# USBTLLHS_ULPI register map
Vendor: Texas Instruments
Peripheral module from a debugger description file (folder omap4460).
Registers are 8-bit, access per field, reset values left out (the file's numbers can be read two ways) unless marked. A register's access mark holds for its fields unless they carry their own. Offsets are as the file gives them; lines under a group give offsets from that group; [hi:lo] are bit positions; {n}, {i} and the like mark numbered series; 'fields as' and 'values as' point back to an identical list; <NAME> marks a mode.

## USBTLLHS_ULPI
0x00 VENDOR_ID_LO_i_0 ro — Lower byte of USB-IF-supplied 16-bit vendor ID Value is set for all channels. Default is Texas Instruments Vendor ID = 0x0451.
  [7:0] VENDOR_ID_LO
0x01 VENDOR_ID_HI_i_0 ro — Upper byte of USB-IF-supplied 16-bit vendor ID Value is set for all channels. Default is Texas-Instruments Vendor ID = 0x0451.
  [7:0] VENDOR_ID_HI
0x02 PRODUCT_ID_LO_i_0 ro — Lower byte of 16-bit product ID Value is set for all channels. Default is
  [7:0] PRODUCT_ID_LO
0x03 PRODUCT_ID_HI_i_0 ro — Upper byte of 16-bit product ID Value is set for all channels. Default is
  [7:0] PRODUCT_ID_HI
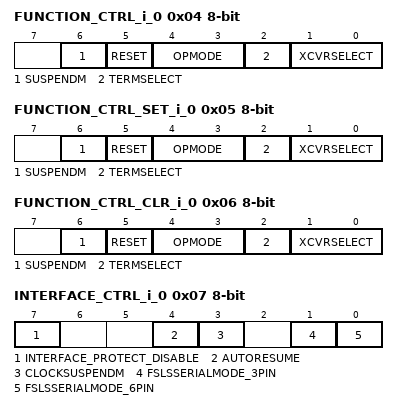
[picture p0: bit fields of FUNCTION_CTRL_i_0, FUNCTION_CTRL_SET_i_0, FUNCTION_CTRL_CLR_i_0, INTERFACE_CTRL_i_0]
0x04 FUNCTION_CTRL_i_0 — Controls UTMI function settings of the PHY. Read/write address.
  [6] SUSPENDM rw — Active low PHY suspend: puts the ULPI bus in low-power mode. Automatically set back to 1 upon low-power mode exit.
    0=PHY is in low-power mode; 1=PHY is not in low-power mode
  [5] RESET rw — Active high UTMI transceiver reset. Auto-cleared. Does not reset the ULPI interface or ULPI register set.
    0=No ongoing reset/no action; 1=Ongoing reset/apply reset
  [4:3] OPMODE rw — Select the required bit encoding style during transmit
    0=Normal operation; 1=Nondriving; 2=Disable bit-stuff and NRZI encoding
  [2] TERMSELECT rw — Controls the internal 1.5-kΩ HS terminations. Control over bus resistors changes depending on XcvrSelect, OpMode, DpPulldown and DmPulldown.
    0=HS termination enabled (other conditions); 1=FS termination enabled (other conditions)
  [1:0] XCVRSELECT rw — Select the required transceiver speed.
    0=Enable HS transceiver; 1=Enable FS transceiver; 3=Enable FS transceiver for LS packets (automatic FS preamble prepending); 2=Enable LS transceiver
0x05 FUNCTION_CTRL_SET_i_0 — Controls UTMI function settings of the PHY. Read/set address (write 1 to a bit to set it to 1, writing 0 has no effect on bit value). See the field description at the read/write address of the same register.
  [6] SUSPENDM rw — Active low PHY suspend: Puts the ULPI bus in low-power mode. Automatically set back to 1 upon low-power mode exit.
    0=SUSPENDM_0_w (No effect on bit value); 1=SUSPENDM_1_w (Set the bit to 1.)
  [5] RESET rw — Active high UTMI transceiver reset. Autocleared. Does not reset the ULPI interface or ULPI register set.
    0=RESET_0_w (No effect on bit value); 1=RESET_1_w (Set the bit to 1.)
  [4:3] OPMODE rw — Select the required bit encoding style during transmit.
    0=OPMODE_0_w (No effect on bit value); 1=OPMODE_1_w (Set the bit to 1.)
  [2] TERMSELECT rw — Controls the internal 1.5-kΩ pullup resistor and 45-Ω HS terminations. Control over bus resistors changes depending on XcvrSelect, OpMode, DpPulldown and DmPulldown.
    0=TERMSELECT_0_w (No effect on bit value); 1=TERMSELECT_1_w (Set the bit to 1.)
  [1:0] XCVRSELECT rw — Select the required transceiver speed.
    0=XCVRSELECT_0_w (No effect on bit value); 1=XCVRSELECT_1_w (Set the bit to 1.)
0x06 FUNCTION_CTRL_CLR_i_0 — Controls UTMI function settings of the PHY. Read/clear address (write 1 to a bit to clear it to 0, writing 0 has no effect on bit value). See the field description at the read/write address of the same register.
  [6] SUSPENDM rw — Active low PHY suspend: Puts the ULPI bus in low-power mode. Automatically set back to 1 upon low-power mode exit.
    0=SUSPENDM_0_w (No effect on bit value); 1=SUSPENDM_1_w (Clear the bit to 0.)
  [5] RESET rw — Active high UTMI transceiver reset. Autocleared. Does not reset the ULPI interface or ULPI register set.
    0=RESET_0_w (No effect on bit value); 1=RESET_1_w (Clear the bit to 0.)
  [4:3] OPMODE rw — Select the required bit encoding style during transmit
    0=OPMODE_0_w (No effect on bit value); 1=OPMODE_1_w (Clear the bit to 0.)
  [2] TERMSELECT rw — Controls the internal 1.5-kΩ pull-up resistor and 45-Ω HS terminations. Control over bus resistors changes depending on XcvrSelect, OpMode, DpPulldown and DmPulldown.
    0=TERMSELECT_0_w (No effect on bit value); 1=TERMSELECT_1_w (Clear the bit to 0.)
  [1:0] XCVRSELECT rw — Select the required transceiver speed.
    0=XCVRSELECT_0_w (No effect on bit value); 1=XCVRSELECT_1_w (Clear the bit to 0.)
0x07 INTERFACE_CTRL_i_0 — Enables alternative interfaces and PHY features. Read/write address.
  [7] INTERFACE_PROTECT_DISABLE rw — Controls circuitry built into the PHY for protecting the ULPI interface when the link 3-states stp and data.
    0=Enables the interface protect circuit; 1=Disables the interface protect circuit
  [4] AUTORESUME rw — Enables the PHY to automatically drive resume signaling. On by default.
    0=AutoResume disabled; 1=AutoResume enabled
  [3] CLOCKSUSPENDM rw — Active low clock suspend for serial modes (6-pin/3-pin).
    0=ULPI clock will stop during serial modes; 1=ULPI clock will run during serial modes
  [1] FSLSSERIALMODE_3PIN rw — Sets the ULPI interface to 3-pin (FS/LS only) serial mode. Auto-cleared when serial mode is exited.
    0=ULPI is not in 3-pin mode; 1=ULPI is in 3-pin serial mode
  [0] FSLSSERIALMODE_6PIN rw — Sets the ULPI interface to 6-pin (FS/LS only) serial mode. Auto-cleared when serial mode is exited.
    0=ULPI is not in 6-pin mode; 1=ULPI is in 6-pin serial mode
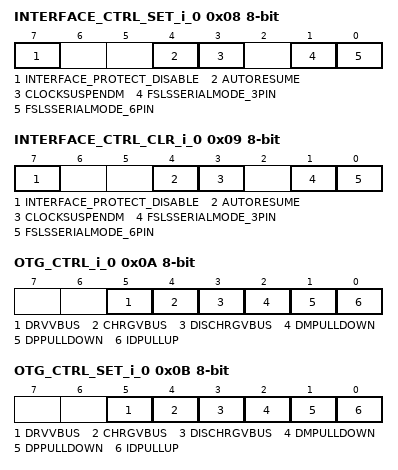
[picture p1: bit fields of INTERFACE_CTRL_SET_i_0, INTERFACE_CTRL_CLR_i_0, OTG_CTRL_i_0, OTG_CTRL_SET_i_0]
0x08 INTERFACE_CTRL_SET_i_0 — Enables alternative interfaces and PHY features. Read/set address (write 1 to a bit to set it to 1, writing 0 has no effect on bit value). See field description at the read/write address of the same register.
  [7] INTERFACE_PROTECT_DISABLE rw — Controls circuitry built into the PHY for protecting the ULPI interface when the link 3-states stp and data.
    0=INTERFACE_PROTECT_DISABLE_0_w (No effect on bit value); 1=INTERFACE_PROTECT_DISABLE_1_w (Set the bit to 1.)
  [4] AUTORESUME rw — Enables the PHY to automatically drive resume signaling. On by default.
    0=AUTORESUME_0_w (No effect on bit value); 1=AUTORESUME_1_w (Set the bit to 1.)
  [3] CLOCKSUSPENDM rw — Active low clock suspend for serial modes (6-pin/3-pin).
    0=CLOCKSUSPENDM_0_w (No effect on bit value); 1=CLOCKSUSPENDM_1_w (Set the bit to 1.)
  [1] FSLSSERIALMODE_3PIN rw — Sets the ULPI interface to 3-pin (FS/LS only) serial mode. Autocleared when serial mode is exited.
    0=FSLSSERIALMODE_3PIN_0_w (No effect on bit value); 1=FSLSSERIALMODE_3PIN_1_w (Set the bit to 1.)
  [0] FSLSSERIALMODE_6PIN rw — Sets the ULPI interface to 6-pin (FS/LS only) serial mode. Autocleared when serial mode is exited.
    0=FSLSSERIALMODE_6PIN_0_w (No effect on bit value); 1=FSLSSERIALMODE_6PIN_1_w (Set the bit to 1.)
0x09 INTERFACE_CTRL_CLR_i_0 — Enables alternative interfaces and PHY features. Read/clear address (write 1 to a bit to clear it to 0, writing 0 has no effect on bit value). See fields description at the read/write address of the same register.
  [7] INTERFACE_PROTECT_DISABLE rw — Controls circuitry built into the PHY for protecting the ULPI interface when the link 3-states stp and data.
    0=INTERFACE_PROTECT_DISABLE_0_w (No effect on bit value); 1=INTERFACE_PROTECT_DISABLE_1_w (Clear the bit to 0.)
  [4] AUTORESUME rw — Enables the PHY to automatically drive resume signaling. On by default.
    0=AUTORESUME_0_w (No effect on bit value); 1=AUTORESUME_1_w (Clear the bit to 0.)
  [3] CLOCKSUSPENDM rw — Active low clock suspend for serial modes (6-pin/3-pin).
    0=CLOCKSUSPENDM_0_w (No effect on bit value); 1=CLOCKSUSPENDM_1_w (Clear the bit to 0.)
  [1] FSLSSERIALMODE_3PIN rw — Sets the ULPI interface to 3-pin (FS/LS only) serial mode. Autocleared when serial mode is exited.
    0=FSLSSERIALMODE_3PIN_0_w (No effect on bit value); 1=FSLSSERIALMODE_3PIN_1_w (Clear the bit to 0.)
  [0] FSLSSERIALMODE_6PIN rw — Sets the ULPI interface to 6-pin (FS/LS only) serial mode. Autocleared when serial mode is exited.
    0=FSLSSERIALMODE_6PIN_0_w (No effect on bit value); 1=FSLSSERIALMODE_6PIN_1_w (Clear the bit to 0.)
0x0A OTG_CTRL_i_0 — Controls UTMI+ OTG functions of the PHY. Read/write address.
  [5] DRVVBUS rw — Drive 5 V on VBUS
    0=No action; 1=Drive VBUS
  [4] CHRGVBUS rw — Charge VBUS through a resistor for VBUS-pulsing SRP.
    0=No action; 1=Charge VBUS
  [3] DISCHRGVBUS rw — Discharge VBUS through a resistor, until the session-end VBUS state is reached.
    0=No action; 1=Discharge VBUS
  [2] DMPULLDOWN rw — Enables the 15-kΩ pulldown resistor on D–
    0=Pulldown resistor not connected to D–; 1=Pulldown resistor connected to D–
  [1] DPPULLDOWN rw — Enables the 15-kΩ pulldown resistor on D+
    0=Pulldown resistor not connected to D+; 1=Pulldown resistor connected to D+
  [0] IDPULLUP rw — Pullup to the (OTG) ID line to allow its sampling
    0=Disable sampling of ID line; 1=Enable sampling of ID line
0x0B OTG_CTRL_SET_i_0 — Controls UTMI+ OTG functions of the PHY. Read/set address (write 1 to a bit to set it to 1, writing 0 has no effect on bit value). See field description at the read/write address of the same register.
  [5] DRVVBUS rw — Drive 5 V on VBUS
    0=DRVVBUS_0_w (No effect on bit value); 1=DRVVBUS_1_w (Set the bit to 1.)
  [4] CHRGVBUS rw — Charge VBUS through a resistor for VBUS-pulsing SRP.
    0=CHRGVBUS_0_w (No effect on bit value); 1=Set the bit to 1
  [3] DISCHRGVBUS rw — Discharge VBUS through a resistor, until the session-end VBUS state is reached.
    0=DISCHRGVBUS_0_w (No effect on bit value); 1=DISCHRGVBUS_1_w (Set the bit to 1.)
  [2] DMPULLDOWN rw — Enables the 15-kΩ pulldown resistor on D–
    0=DMPULLDOWN_0_w (No effect on bit value); 1=DMPULLDOWN_1_w (Set the bit to 1.)
  [1] DPPULLDOWN rw — Enables the 15-kΩ pulldown resistor on D+
    0=DPPULLDOWN_0_w (No effect on bit value); 1=DPPULLDOWN_1_w (Set the bit to 1.)
  [0] IDPULLUP rw — Pullup to the (OTG) ID line to allow its sampling
    0=IDPULLUP_0_w (No effect on bit value); 1=IDPULLUP_1_w (Set the bit to 1.)
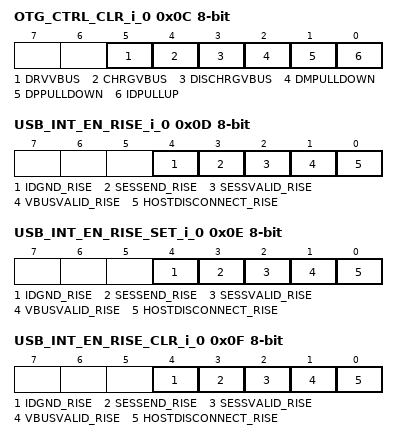
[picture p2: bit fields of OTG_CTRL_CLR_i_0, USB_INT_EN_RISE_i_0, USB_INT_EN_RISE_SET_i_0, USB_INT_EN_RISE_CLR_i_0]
0x0C OTG_CTRL_CLR_i_0 — Controls UTMI+ OTG functions of the PHY. Read/clear address (write 1 to a bit to clear it to 0, writing 0 has no effect on bit value). See fields description at the read/write address of the same register.
  [5] DRVVBUS rw — Drive 5 V on VBUS
    0=DRVVBUS_0_w (No effect on bit value); 1=DRVVBUS_1_w (Clear the bit to 0.)
  [4] CHRGVBUS rw — Charge VBUS through a resistor for VBUS-pulsing SRP.
    0=CHRGVBUS_0_w (No effect on bit value); 1=CHRGVBUS_1_w (Clear the bit to 0.)
  [3] DISCHRGVBUS rw — Discharge VBUS through a resistor, until the session-end VBUS state is reached.
    0=DISCHRGVBUS_0_w (No effect on bit value); 1=DISCHRGVBUS_1_w (Clear the bit to 0.)
  [2] DMPULLDOWN rw — Enables the 15k pulldown resistor on D–
    0=DMPULLDOWN_0_w (No effect on bit value); 1=DMPULLDOWN_1_w (Clear the bit to 0.)
  [1] DPPULLDOWN rw — Enables the 15kΩ pulldown resistor on D+
    0=DPPULLDOWN_0_w (No effect on bit value); 1=DPPULLDOWN_1_w (Clear the bit to 0.)
  [0] IDPULLUP rw — Pullup to the (OTG) ID line to allow its sampling
    0=IDPULLUP_0_w (No effect on bit value); 1=IDPULLUP_1_w (Clear the bit to 0.)
0x0D USB_INT_EN_RISE_i_0 — Enables an interrupt event notification when the corresponding status bit changes from low to high. By default, all transitions are enabled. Read/write address.
  [4] IDGND_RISE rw — Generate an interrupt event notification when IdGnd changes from low to high. Event is automatically masked if IdPullup bit is clear to 0 and for 50ms after IdPullup is set to 1.
    0=IDGND_RISE_0_w (No effect on bit value); 1=IDGND_RISE_1_w (Set the bit to 1)
  [3] SESSEND_RISE rw — Generate an interrupt event notification when SessEnd changes from low to high.
    0=SESSEND_RISE_0_w (No effect on bit value); 1=SESSEND_RISE_1_w (Set the bit to 1)
  [2] SESSVALID_RISE rw — Generate an interrupt event notification when SessValid changes from low to high. SessValid is the same as UTMI+ AValid.
    0=SESSVALID_RISE_0_w (No effect on bit value); 1=SESSVALID_RISE_1_w (Set the bit to 1)
  [1] VBUSVALID_RISE rw — Generate an interrupt event notification when VbusValid changes from low to high.
    0=VBUSVALID_RISE_0_w (No effect on bit value); 1=VBUSVALID_RISE_1_w (Set the bit to 1)
  [0] HOSTDISCONNECT_RISE rw — Generate an interrupt event notification when Hostdisconnect changes from low to high. Applicable only in host mode (DpPulldown and DmPulldown both set to 1b).
    0=HOSTDISCONNECT_RISE_0_w (No effect on bit value); 1=HOSTDISCONNECT_RISE_1_w (Set the bit to 1)
0x0E USB_INT_EN_RISE_SET_i_0 — Enables an interrupt event notification when the corresponding status bit changes from low to high. Read/set address (write 1 to a bit to set it to 1, writing 0 has no effect on bit value). See fields description at the read/write address of the same register.
  [4] IDGND_RISE rw — Generate an interrupt event notification when IdGnd changes from low to high. Event is automatically masked if IdPullup bit is clear to 0 and for 50ms after IdPullup is set to 1.
    0=IDGND_RISE_0_w (No effect on bit value); 1=IDGND_RISE_1_w (Set the bit to 1.)
  [3] SESSEND_RISE rw — Generate an interrupt event notification when SessEnd changes from low to high.
    0=SESSEND_RISE_0_w (No effect on bit value); 1=SESSEND_RISE_1_w (Set the bit to 1.)
  [2] SESSVALID_RISE rw — Generate an interrupt event notification when SessValid changes from low to high. SessValid is the same as UTMI+ AValid.
    0=SESSVALID_RISE_0_w (No effect on bit value); 1=SESSVALID_RISE_1_w (Set the bit to 1.)
  [1] VBUSVALID_RISE rw — Generate an interrupt event notification when VbusValid changes from low to high.
    0=VBUSVALID_RISE_0_w (No effect on bit value); 1=VBUSVALID_RISE_1_w (Set the bit to 1.)
  [0] HOSTDISCONNECT_RISE rw — Generate an interrupt event notification when Hostdisconnect changes from low to high. Applicable only in host mode (DpPulldown and DmPulldown both set to 1b).
    0=HOSTDISCONNECT_RISE_0_w (No effect on bit value); 1=HOSTDISCONNECT_RISE_1_w (Set the bit to 1.)
0x0F USB_INT_EN_RISE_CLR_i_0 — Enables an interrupt event notification when the corresponding status bit changes from low to high. Read/clear address (write 1 to a bit to clear it to 0, writing 0 has no effect on bit value). See the field description at the read/write address of the same register.
  [4] IDGND_RISE rw — Generate an interrupt event notification when IdGnd changes from low to high. Event is automatically masked if IdPullup bit is clear to 0 and for 50 ms after IdPullup is set to 1.
    0=IDGND_RISE_0_w (No effect on bit value); 1=IDGND_RISE_1_w (Clear the bit to 0.)
  [3] SESSEND_RISE rw — Generate an interrupt event notification when SessEnd changes from low to high.
    0=SESSEND_RISE_0_w (No effect on bit value); 1=SESSEND_RISE_1_w (Clear the bit to 0.)
  [2] SESSVALID_RISE rw — Generate an interrupt event notification when SessValid changes from low to high. SessValid is the same as UTMI+ AValid.
    0=SESSVALID_RISE_0_w (No effect on bit value); 1=SESSVALID_RISE_1_w (Clear the bit to 0.)
  [1] VBUSVALID_RISE rw — Generate an interrupt event notification when VbusValid changes from low to high.
    0=VBUSVALID_RISE_0_w (No effect on bit value); 1=VBUSVALID_RISE_1_w (Clear the bit to 0.)
  [0] HOSTDISCONNECT_RISE rw — Generate an interrupt event notification when Hostdisconnect changes from low to high. Applicable only in host mode (DpPulldown and DmPulldown both set to 1b).
    0=HOSTDISCONNECT_RISE_0_w (No effect on bit value); 1=HOSTDISCONNECT_RISE_1_w (Clear the bit to 0.)
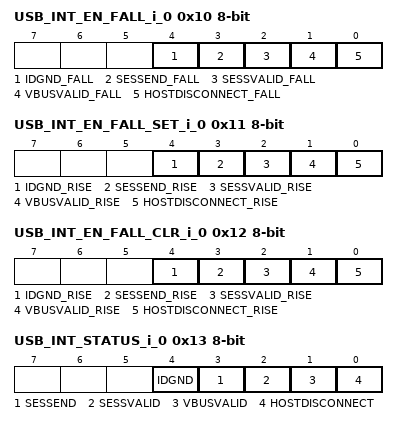
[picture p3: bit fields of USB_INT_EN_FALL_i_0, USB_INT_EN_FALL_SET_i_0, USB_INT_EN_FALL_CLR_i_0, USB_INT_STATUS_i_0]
0x10 USB_INT_EN_FALL_i_0 — Enables an interrupt event notification when the corresponding status bit changes from high to low. By default, all transitions are enabled. Read/write address.
  [4] IDGND_FALL rw — Generate an interrupt event notification when IdGnd changes from high to low. Event is automatically masked if IdPullup bit is clear to 0 and for 50 ms after IdPullup is set to 1.
  [3] SESSEND_FALL rw — Generate an interrupt event notification when SessEnd changes from high to low.
  [2] SESSVALID_FALL rw — Generate an interrupt event notification when SessValid changes from high to low. SessValid is the same as UTMI+ AValid.
  [1] VBUSVALID_FALL rw — Generate an interrupt event notification when VbusValid changes from high to low.
  [0] HOSTDISCONNECT_FALL rw — Generate an interrupt event notification when Hostdisconnect changes from high to low. Applicable only in host mode (DpPulldown and DmPulldown both set to 1b).
0x11 USB_INT_EN_FALL_SET_i_0 — Enables an interrupt event notification when the corresponding status bit changes from high to low. Read/set address (write 1 to a bit to set it to 1, writing 0 has no effect on bit value). See fields description at the read/write address of the same register.
  [4] IDGND_RISE rw — Generate an interrupt event notification when IdGnd changes from low to high. Event is automatically masked if IdPullup bit is clear to 0 and for 50 ms after IdPullup is set to 1.
    values as USB_INT_EN_RISE_SET_i_0.IDGND_RISE
  [3] SESSEND_RISE rw — Generate an interrupt event notification when SessEnd changes from low to high.
    values as USB_INT_EN_RISE_SET_i_0.SESSEND_RISE
  [2] SESSVALID_RISE rw — Generate an interrupt event notification when SessValid changes from low to high. SessValid is the same as UTMI+ AValid.
    values as USB_INT_EN_RISE_SET_i_0.SESSVALID_RISE
  [1] VBUSVALID_RISE rw — Generate an interrupt event notification when VbusValid changes from low to high.
    values as USB_INT_EN_RISE_SET_i_0.VBUSVALID_RISE
  [0] HOSTDISCONNECT_RISE rw — Generate an interrupt event notification when Hostdisconnect changes from low to high. Applicable only in host mode (DpPulldown and DmPulldown both set to 1b).
    values as USB_INT_EN_RISE_SET_i_0.HOSTDISCONNECT_RISE
0x12 USB_INT_EN_FALL_CLR_i_0 — Enables an interrupt event notification when the corresponding status bit changes from high to low. Read/clear address (write 1 to a bit to clear it to 0, writing 0 has no effect on bit value). See field description at the read/write address of the same register.
  fields as USB_INT_EN_RISE_CLR_i_0
0x13 USB_INT_STATUS_i_0 ro — Indicates the current value of the interrupt source signal.
  [4] IDGND — Value of UTMI+ IdDig output. Undefined unless IdPullup = 1
    1=IDGND_1_r (ID pin is floating = OTG B = default peripheral); 0=IDGND_0_r (ID pin is grounded = OTG A = default host)
  [3] SESSEND — Current value of UTMI+ SessEnd output.
    1=SESSEND_1_r (VBUS is below Session-End threshold.); 0=SESSEND_0_r (VBUS is above Session-End threshold.)
  [2] SESSVALID — Current value of UTMI+ SessValid output. SessValid is the same as UTMI+ AValid.
    1=SESSVALID_1_r (VBUS is above Session-Valid threshold.); 0=SESSVALID_0_r (VBUS is below Session-Valid threshold.)
  [1] VBUSVALID — Current value of UTMI+ VbusValid output.
    1=VBUSVALID_1_r (VBUS is above Vbus-Valid threshold.); 0=VBUSVALID_0_r (VBUS is below Vbus-Valid threshold.)
  [0] HOSTDISCONNECT — Current value of UTMI+ Hostdisconnect output. Applicable only in host mode. Automatically reset to 0 when low-power mode is entered.
    1=HOSTDISCONNECT_1_r (Peripheral disconnected); 0=HOSTDISCONNECT_0_r (Peripheral not disconnected or nonhost mode)
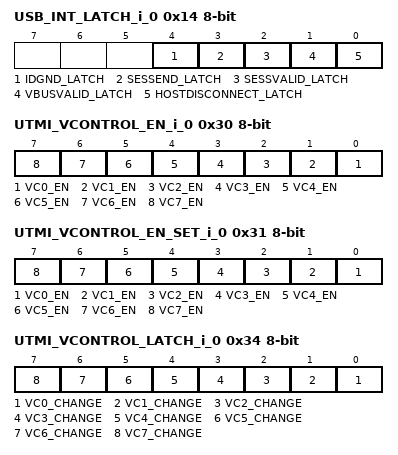
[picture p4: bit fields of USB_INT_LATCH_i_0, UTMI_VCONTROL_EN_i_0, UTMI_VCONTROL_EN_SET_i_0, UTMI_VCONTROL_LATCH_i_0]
0x14 USB_INT_LATCH_i_0 ro — Set by unmasked changes on the corresponding status bits to generate the ULPI interrupt. Cleared upon read, and when low-power mode, serial mode, or carkit mode are entered.
  [4] IDGND_LATCH — Set to 1 by the PHY when an unmasked event occurs on IdGnd. Cleared when this register is read.
  [3] SESSEND_LATCH — Set to 1 by the PHY when an unmasked event occurs on SessEnd. Cleared when this register is read.
  [2] SESSVALID_LATCH — Set to 1 by the PHY when an unmasked event occurs on SessValid. Cleared when this register is read. SessValid is the same as UTMI+ AValid.
  [1] VBUSVALID_LATCH — Set to 1 by the PHY when an unmasked event occurs on VbusValid. Cleared when this register is read.
  [0] HOSTDISCONNECT_LATCH — Set to 1 by the PHY when an unmasked event occurs on Hostdisconnect. Cleared when this register is read. Applicable only in host mode.
0x15 DEBUG_i_0 ro — Indicates the current value of various signals useful for debugging.
  [1:0] LINE_STATE — Current state of the USB line: D+ (bit 0) and D– (bit 1).
    3=LINE_STATE_3_r (SE1 (LS/FS), Invalid (HS/Chirp)); 2=LINE_STATE_2_r (LS: J state, FS: K state, HS: Invalid, Chirp: !Squelch AND !HS_Differential_Receiver_Output); 1=LINE_STATE_1_r (LS: K state, FS: J state, HS: !Squelch, Chirp: !Squelch AND HS_Differential_Receiver_Output); 0=LINE_STATE_0_r (SE0 (LS/FS), Squelch (HS/Chirp))
0x16 SCRATCH_REGISTER_i_0 rw — Register byte for register access testing purposes. Value has no functional effect on PHY. Read/write address.
  [7:0] SCRATCH — Scratch data
0x17 SCRATCH_REGISTER_SET_i_0 rw — Register byte for register access testing purposes. Value has no functional effect on PHY. Read/set address (write 1 to a bit to set it to 1, writing 0 has no effect on bit value). See field description at the read/write address of the same register.
  [7:0] SCRATCH — Scratch data Write 1 to a bit to set it to 1. Writing 0 has no effect on bit value.
0x18 SCRATCH_REGISTER_CLR_i_0 rw — Register byte for register access testing purposes. Value has no functional effect on PHY. Read/clear address (write 1 to a bit to clear it to 0, writing 0 has no effect on bit value). See field description at the read/write address of the same register.
  [7:0] SCRATCH — Scratch data Write 1 to a bit to clear it to 0. Writing 0 has no effect on bit value.
0x2F EXTENDED_SET_ACCESS_i_0 rw — This address is used to access the extended register set; that is, addresses above 0x40.
  [7:0] SET_ACCESS — This bit field is used to access the extended register set; that is, addresses above 0x40.
0x30 UTMI_VCONTROL_EN_i_0 rw — Part of nonstandard UTMI-to-ULPI mailbox system, implemented if HDL generic VCS_MAILBOX bit is 1 Enables an interrupt notification when the corresponding vcontrol_status bit changes. Read/write address. Lowest VCS_CTRL_WIDTH (HDL generic) bits are implemented, others are always-0, read-only. (UTMI standard is 4-bit.)
  [n] VC{n}_EN (n=0..7) — Enable alt_int assertion upon vcontrol_status bit change: Write 0x0: No effect on bit value Write 0x1: Set the bit to 1.
0x31 UTMI_VCONTROL_EN_SET_i_0 rw — Part of nonstandard UTMI-to-ULPI mailbox system, implemented if HDL generic VCS_MAILBOX bit is 1 Enables an interrupt notification when the corresponding vcontrol_status bit changes. Read/set address (write 1 to a bit to set it to 1, writing 0 has no effect on bit value). See fields description at the read/write address of the same register.
  fields as UTMI_VCONTROL_EN_i_0
0x32 UTMI_VCONTROL_EN_CLR_i_0 rw — Part of nonstandard UTMI-to-ULPI mailbox system, implemented if HDL generic VCS_MAILBOX bit is 1. Enables an interrupt notification when the corresponding vcontrol_status bit changes. Read/clear address (write 1 to a bit to clear it to 0, writing 0 has no effect on bit value). See fields description at the read/write address of the same register.
  [7:0] VC — User-defined UTMI control data byte
0x33 UTMI_VCONTROL_STATUS_i_0 rw — Part of nonstandard UTMI-to-ULPI mailbox system, implemented if HDL generic VCS_MAILBOX bit is 1. UTMI-standard Vcontrol vector byte is sent by the UTMI controller (other side of TLL) to its PHY (emulated here by the TLL). Alternatively, data can be also written directly into the register. Can contain any user-defined data. Vcontrol bit changes can be used to assert the ULPI ALT interrupt. Lowest VCS_CTRL_WIDTH (HDL generic) bits are implemented, others are always-0, read-only. (UTMI standard is 4-bit).
  [7:0] VC — User-defined UTMI Control data byte
0x34 UTMI_VCONTROL_LATCH_i_0 ro — Part of nonstandard UTMI-to-ULPI mailbox system, implemented if HDL generic VCS_MAILBOX bit is 1. Set by unmasked changes on the corresponding vcontrol_status bits to generate the ULPI ALT interrupt. Cleared upon read, and when low-power mode, serial mode or carkit mode are entered. Lowest VCS_CTRL_WIDTH (HDL generic) bits are implemented, others are always-0, read-only. (UTMI standard is 4-bit.)
  [n] VC{n}_CHANGE (n=0..7) — Unmasked change on vcontrol_status bit
0x35 UTMI_VSTATUS_i_0 rw — Part of nonstandard UTMI-to-ULPI mailbox system, implemented if HDL generic VCS_MAILBOX bit is 1. UTMI-standard Vstatus vector byte is sent by the PHY (emulated here by the TLL) to the UTMI controller (other side of TLL): information written into this register goes directly to the UTMI controller, and can contain any user-defined data. Read/write address. Lowest VCS_STAT_WIDTH (HDL generic) bits are implemented, others are always-0, read-only. (UTMI standard is 8-bit.)
  [7:0] VS — User-defined UTMI status data byte
0x36 UTMI_VSTATUS_SET_i_0 rw — Part of nonstandard UTMI-to-ULPI mailbox system, implemented if HDL generic VCS_MAILBOX bit is 1. UTMI-standard Vstatus vector byte is sent by the PHY (emulated here by the TLL) to the UTMI controller (other side of TLL): information written into this register goes directly to the UTMI controller, and can contain any user-defined data. Read/set address (write 1 to a bit to set it to 1, writing 0 has no effect on bit value). See field description at the read/write address of the same register.
  [7:0] VS — User-defined UTMI status data byte Write 0x0: No effect on bit value Write 0x1: Set the bit to 1.
0x37 UTMI_VSTATUS_CLR_i_0 rw — Part of nonstandard UTMI-to-ULPI mailbox system, implemented if HDL generic VCS_MAILBOX bit is 1. UTMI-standard Vstatus vector byte is sent by the PHY (emulated here by the TLL) to the UTMI controller (other side of TLL): information written into this register goes directly to the UTMI controller, and can contain any user-defined data. Read/clear address (write 1 to a bit to clear it to 0, writing 0 has no effect on bit value). See field description at the read/write address of the same register.
  [7:0] VS — User-defined UTMI status data byte: Write 0x0: No effect on bit value Write 0x1: Clear the bit to 0.
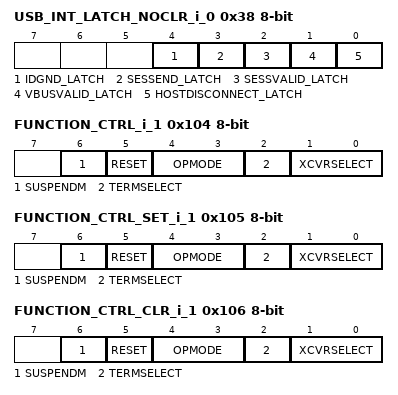
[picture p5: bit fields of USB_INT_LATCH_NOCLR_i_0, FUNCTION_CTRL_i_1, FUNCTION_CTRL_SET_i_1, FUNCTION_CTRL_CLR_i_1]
0x38 USB_INT_LATCH_NOCLR_i_0 ro — Set by unmasked changes on the corresponding status bits to generate the ULPI interrupt. Debug, nonstandard address to the standard register: Register is not cleared on read. See field description at the 'clear-on-read' address of the same register.
  [4] IDGND_LATCH — Set to 1 by the PHY when an unmasked event occurs on IdGnd.
  [3] SESSEND_LATCH — Set to 1 by the PHY when an unmasked event occurs on SessEnd.
  [2] SESSVALID_LATCH — Set to 1 by the PHY when an unmasked event occurs on SessValid. SessValid is the same as UTMI+ AValid.
  [1] VBUSVALID_LATCH — Set to 1 by the PHY when an unmasked event occurs on VbusValid.
  [0] HOSTDISCONNECT_LATCH — Set to 1 by the PHY when an unmasked event occurs on Hostdisconnect. Applicable only in host mode.
0x3B VENDOR_INT_EN_i_0 — Vendor-specific interrupt enables (mask) for miscellaneous ULPI alt_int events. Read/write address.
  [0] P2P_EN rw — Enable PHY-to-PHY ULPI wakeup upon inactive UTMI suspendm.
    0=PHY-to-PHY wakeup enabled; 1=PHY-to-PHY wakeup enabled
0x3C VENDOR_INT_EN_SET_i_0 — Vendor-specific interrupt enable bit (mask) for miscellaneous ULPI alt_int events. Read/set address (write 1 to a bit to set it to 1, writing 0 has no effect on bit value). See field description at the read/write address of the same register.
  [0] P2P_EN rw — Enable PHY-to-PHY ULPI wakeup upon inactive UTMI suspendm.
    0=P2P_EN_0_w (No effect on bit value); 1=P2P_EN_1_w (Set the bit to 1.)
0x3D VENDOR_INT_EN_CLR_i_0 — Vendor-specific interrupt enables (mask) for miscellaneous ULPI alt_int events. Read/clear address (write 1 to a bit to clear it to 0, writing 0 has no effect on bit value). See fields description at the read/write address of the same register.
  [0] P2P_EN rw — Enable PHY-to-PHY ULPI wakeup upon inactive UTMI suspendm.
    0=P2P_EN_0_w (No effect on bit value); 1=P2P_EN_1_w (Clear the bit to 0.)
0x3E VENDOR_INT_STATUS_i_0 ro — Vendor-specific interrupt sources for miscellaneous ULPI alt_int events
  [0] UTMI_SUSPENDM — UTMI suspendm status (active-low), source of TLL PHY-to-PHY wake-up interrupt.
    1=UTMI_SUSPENDM_1_r (UTMI interface is active (not suspended).); 0=UTMI_SUSPENDM_0_r (UTMI interface is suspended.)
0x3F VENDOR_INT_LATCH_i_0 ro — Vendor-specific interrupt latches for miscellaneous ULPI alt_int events. Cleared upon read, and when low-power mode, serial mode or carkit mode are entered.
  [0] P2P_LATCH — PHY-to-PHY ULPI wake-up event latch. Set when ULPI is in low-power mode (suspendm = 0) and UTMI is active (suspendm = 1).
    1=P2P_LATCH_1_r (PHY-to-PHY wake-up event was latched, ALT interrupt active.); 0=P2P_LATCH_0_r (No PHY-to-PHY wake-up event was latched.)
0x100 VENDOR_ID_LO_i_1 ro — Lower byte of USB-IF-supplied 16-bit vendor ID Value is set for all channels. Default is Texas Instruments Vendor ID = 0x0451.
  [7:0] VENDOR_ID_LO
0x101 VENDOR_ID_HI_i_1 ro — Upper byte of USB-IF-supplied 16-bit vendor ID Value is set for all channels. Default is Texas-Instruments Vendor ID = 0x0451.
  [7:0] VENDOR_ID_HI
0x102 PRODUCT_ID_LO_i_1 ro — Lower byte of 16-bit product ID Value is set for all channels. Default is
  [7:0] PRODUCT_ID_LO
0x103 PRODUCT_ID_HI_i_1 ro — Upper byte of 16-bit product ID Value is set for all channels. Default is
  [7:0] PRODUCT_ID_HI
0x104 FUNCTION_CTRL_i_1 — Controls UTMI function settings of the PHY. Read/write address.
  fields as FUNCTION_CTRL_i_0
0x105 FUNCTION_CTRL_SET_i_1 — Controls UTMI function settings of the PHY. Read/set address (write 1 to a bit to set it to 1, writing 0 has no effect on bit value). See the field description at the read/write address of the same register.
  fields as FUNCTION_CTRL_SET_i_0
0x106 FUNCTION_CTRL_CLR_i_1 — Controls UTMI function settings of the PHY. Read/clear address (write 1 to a bit to clear it to 0, writing 0 has no effect on bit value). See the field description at the read/write address of the same register.
  fields as FUNCTION_CTRL_CLR_i_0
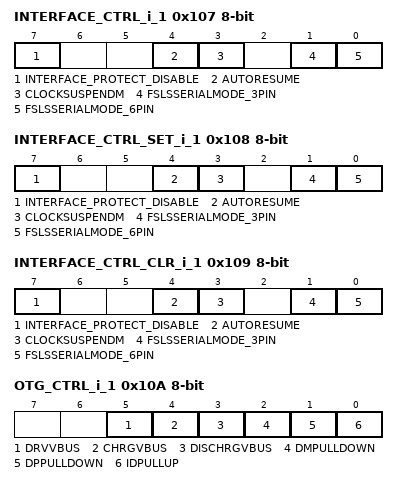
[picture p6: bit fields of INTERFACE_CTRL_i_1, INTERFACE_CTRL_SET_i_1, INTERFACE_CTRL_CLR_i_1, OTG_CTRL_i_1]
0x107 INTERFACE_CTRL_i_1 — Enables alternative interfaces and PHY features. Read/write address.
  fields as INTERFACE_CTRL_i_0
0x108 INTERFACE_CTRL_SET_i_1 — Enables alternative interfaces and PHY features. Read/set address (write 1 to a bit to set it to 1, writing 0 has no effect on bit value). See field description at the read/write address of the same register.
  fields as INTERFACE_CTRL_SET_i_0
0x109 INTERFACE_CTRL_CLR_i_1 — Enables alternative interfaces and PHY features. Read/clear address (write 1 to a bit to clear it to 0, writing 0 has no effect on bit value). See fields description at the read/write address of the same register.
  fields as INTERFACE_CTRL_CLR_i_0
0x10A OTG_CTRL_i_1 — Controls UTMI+ OTG functions of the PHY. Read/write address.
  fields as OTG_CTRL_i_0
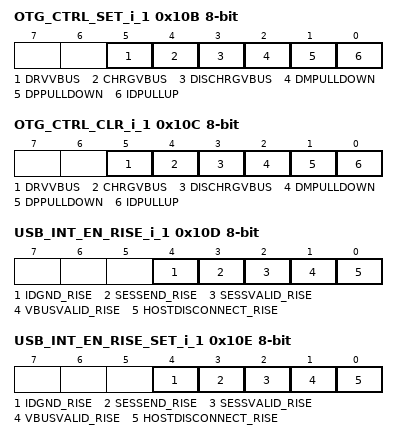
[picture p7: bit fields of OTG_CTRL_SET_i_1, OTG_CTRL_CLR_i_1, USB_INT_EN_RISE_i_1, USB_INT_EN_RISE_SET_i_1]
0x10B OTG_CTRL_SET_i_1 — Controls UTMI+ OTG functions of the PHY. Read/set address (write 1 to a bit to set it to 1, writing 0 has no effect on bit value). See field description at the read/write address of the same register.
  fields as OTG_CTRL_SET_i_0
0x10C OTG_CTRL_CLR_i_1 — Controls UTMI+ OTG functions of the PHY. Read/clear address (write 1 to a bit to clear it to 0, writing 0 has no effect on bit value). See fields description at the read/write address of the same register.
  fields as OTG_CTRL_CLR_i_0
0x10D USB_INT_EN_RISE_i_1 — Enables an interrupt event notification when the corresponding status bit changes from low to high. By default, all transitions are enabled. Read/write address.
  fields as USB_INT_EN_RISE_i_0
0x10E USB_INT_EN_RISE_SET_i_1 — Enables an interrupt event notification when the corresponding status bit changes from low to high. Read/set address (write 1 to a bit to set it to 1, writing 0 has no effect on bit value). See fields description at the read/write address of the same register.
  fields as USB_INT_EN_RISE_SET_i_0
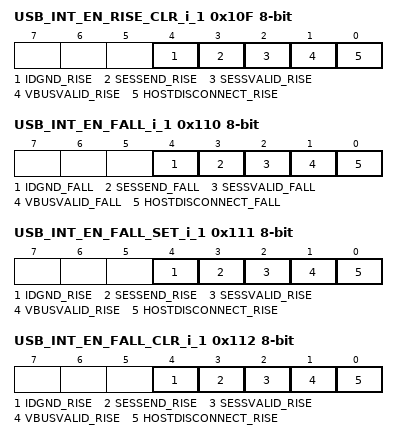
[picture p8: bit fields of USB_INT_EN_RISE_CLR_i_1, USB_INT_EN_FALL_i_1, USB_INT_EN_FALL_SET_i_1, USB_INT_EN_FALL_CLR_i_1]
0x10F USB_INT_EN_RISE_CLR_i_1 — Enables an interrupt event notification when the corresponding status bit changes from low to high. Read/clear address (write 1 to a bit to clear it to 0, writing 0 has no effect on bit value). See the field description at the read/write address of the same register.
  fields as USB_INT_EN_RISE_CLR_i_0
0x110 USB_INT_EN_FALL_i_1 — Enables an interrupt event notification when the corresponding status bit changes from high to low. By default, all transitions are enabled. Read/write address.
  fields as USB_INT_EN_FALL_i_0
0x111 USB_INT_EN_FALL_SET_i_1 — Enables an interrupt event notification when the corresponding status bit changes from high to low. Read/set address (write 1 to a bit to set it to 1, writing 0 has no effect on bit value). See fields description at the read/write address of the same register.
  fields as USB_INT_EN_FALL_SET_i_0
0x112 USB_INT_EN_FALL_CLR_i_1 — Enables an interrupt event notification when the corresponding status bit changes from high to low. Read/clear address (write 1 to a bit to clear it to 0, writing 0 has no effect on bit value). See field description at the read/write address of the same register.
  fields as USB_INT_EN_RISE_CLR_i_0
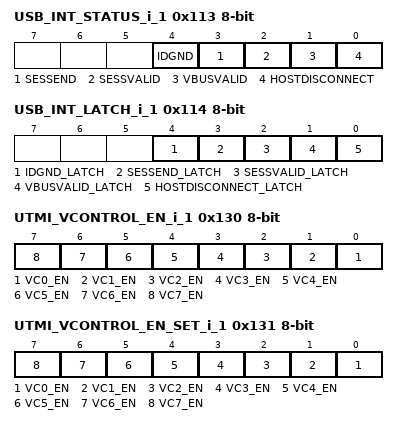
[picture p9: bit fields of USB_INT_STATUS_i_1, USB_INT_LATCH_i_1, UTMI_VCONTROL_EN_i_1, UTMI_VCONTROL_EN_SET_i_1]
0x113 USB_INT_STATUS_i_1 ro — Indicates the current value of the interrupt source signal.
  fields as USB_INT_STATUS_i_0
0x114 USB_INT_LATCH_i_1 ro — Set by unmasked changes on the corresponding status bits to generate the ULPI interrupt. Cleared upon read, and when low-power mode, serial mode, or carkit mode are entered.
  fields as USB_INT_LATCH_i_0
0x115 DEBUG_i_1 ro — Indicates the current value of various signals useful for debugging.
  fields as DEBUG_i_0
0x116 SCRATCH_REGISTER_i_1 rw — Register byte for register access testing purposes. Value has no functional effect on PHY. Read/write address.
  [7:0] SCRATCH — Scratch data
0x117 SCRATCH_REGISTER_SET_i_1 rw — Register byte for register access testing purposes. Value has no functional effect on PHY. Read/set address (write 1 to a bit to set it to 1, writing 0 has no effect on bit value). See field description at the read/write address of the same register.
  fields as SCRATCH_REGISTER_SET_i_0
0x118 SCRATCH_REGISTER_CLR_i_1 rw — Register byte for register access testing purposes. Value has no functional effect on PHY. Read/clear address (write 1 to a bit to clear it to 0, writing 0 has no effect on bit value). See field description at the read/write address of the same register.
  fields as SCRATCH_REGISTER_CLR_i_0
0x12F EXTENDED_SET_ACCESS_i_1 rw — This address is used to access the extended register set; that is, addresses above 0x40.
  fields as EXTENDED_SET_ACCESS_i_0
0x130 UTMI_VCONTROL_EN_i_1 rw — Part of nonstandard UTMI-to-ULPI mailbox system, implemented if HDL generic VCS_MAILBOX bit is 1 Enables an interrupt notification when the corresponding vcontrol_status bit changes. Read/write address. Lowest VCS_CTRL_WIDTH (HDL generic) bits are implemented, others are always-0, read-only. (UTMI standard is 4-bit.)
  fields as UTMI_VCONTROL_EN_i_0
0x131 UTMI_VCONTROL_EN_SET_i_1 rw — Part of nonstandard UTMI-to-ULPI mailbox system, implemented if HDL generic VCS_MAILBOX bit is 1 Enables an interrupt notification when the corresponding vcontrol_status bit changes. Read/set address (write 1 to a bit to set it to 1, writing 0 has no effect on bit value). See fields description at the read/write address of the same register.
  fields as UTMI_VCONTROL_EN_i_0
0x132 UTMI_VCONTROL_EN_CLR_i_1 rw — Part of nonstandard UTMI-to-ULPI mailbox system, implemented if HDL generic VCS_MAILBOX bit is 1. Enables an interrupt notification when the corresponding vcontrol_status bit changes. Read/clear address (write 1 to a bit to clear it to 0, writing 0 has no effect on bit value). See fields description at the read/write address of the same register.
  [7:0] VC — User-defined UTMI control data byte
0x133 UTMI_VCONTROL_STATUS_i_1 rw — Part of nonstandard UTMI-to-ULPI mailbox system, implemented if HDL generic VCS_MAILBOX bit is 1. UTMI-standard Vcontrol vector byte is sent by the UTMI controller (other side of TLL) to its PHY (emulated here by the TLL). Alternatively, data can be also written directly into the register. Can contain any user-defined data. Vcontrol bit changes can be used to assert the ULPI ALT interrupt. Lowest VCS_CTRL_WIDTH (HDL generic) bits are implemented, others are always-0, read-only. (UTMI standard is 4-bit).
  [7:0] VC — User-defined UTMI Control data byte
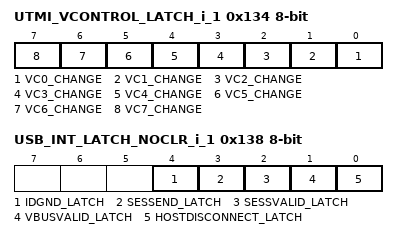
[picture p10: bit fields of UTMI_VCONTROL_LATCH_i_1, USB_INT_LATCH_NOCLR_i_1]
0x134 UTMI_VCONTROL_LATCH_i_1 ro — Part of nonstandard UTMI-to-ULPI mailbox system, implemented if HDL generic VCS_MAILBOX bit is 1. Set by unmasked changes on the corresponding vcontrol_status bits to generate the ULPI ALT interrupt. Cleared upon read, and when low-power mode, serial mode or carkit mode are entered. Lowest VCS_CTRL_WIDTH (HDL generic) bits are implemented, others are always-0, read-only. (UTMI standard is 4-bit.)
  [n] VC{n}_CHANGE (n=0..7) — Unmasked change on vcontrol_status bit
0x135 UTMI_VSTATUS_i_1 rw — Part of nonstandard UTMI-to-ULPI mailbox system, implemented if HDL generic VCS_MAILBOX bit is 1. UTMI-standard Vstatus vector byte is sent by the PHY (emulated here by the TLL) to the UTMI controller (other side of TLL): information written into this register goes directly to the UTMI controller, and can contain any user-defined data. Read/write address. Lowest VCS_STAT_WIDTH (HDL generic) bits are implemented, others are always-0, read-only. (UTMI standard is 8-bit.)
  [7:0] VS — User-defined UTMI status data byte
0x136 UTMI_VSTATUS_SET_i_1 rw — Part of nonstandard UTMI-to-ULPI mailbox system, implemented if HDL generic VCS_MAILBOX bit is 1. UTMI-standard Vstatus vector byte is sent by the PHY (emulated here by the TLL) to the UTMI controller (other side of TLL): information written into this register goes directly to the UTMI controller, and can contain any user-defined data. Read/set address (write 1 to a bit to set it to 1, writing 0 has no effect on bit value). See field description at the read/write address of the same register.
  fields as UTMI_VSTATUS_SET_i_0
0x137 UTMI_VSTATUS_CLR_i_1 rw — Part of nonstandard UTMI-to-ULPI mailbox system, implemented if HDL generic VCS_MAILBOX bit is 1. UTMI-standard Vstatus vector byte is sent by the PHY (emulated here by the TLL) to the UTMI controller (other side of TLL): information written into this register goes directly to the UTMI controller, and can contain any user-defined data. Read/clear address (write 1 to a bit to clear it to 0, writing 0 has no effect on bit value). See field description at the read/write address of the same register.
  fields as UTMI_VSTATUS_CLR_i_0
0x138 USB_INT_LATCH_NOCLR_i_1 ro — Set by unmasked changes on the corresponding status bits to generate the ULPI interrupt. Debug, nonstandard address to the standard register: Register is not cleared on read. See field description at the 'clear-on-read' address of the same register.
  fields as USB_INT_LATCH_NOCLR_i_0
0x13B VENDOR_INT_EN_i_1 — Vendor-specific interrupt enables (mask) for miscellaneous ULPI alt_int events. Read/write address.
  fields as VENDOR_INT_EN_i_0
0x13C VENDOR_INT_EN_SET_i_1 — Vendor-specific interrupt enable bit (mask) for miscellaneous ULPI alt_int events. Read/set address (write 1 to a bit to set it to 1, writing 0 has no effect on bit value). See field description at the read/write address of the same register.
  fields as VENDOR_INT_EN_SET_i_0
0x13D VENDOR_INT_EN_CLR_i_1 — Vendor-specific interrupt enables (mask) for miscellaneous ULPI alt_int events. Read/clear address (write 1 to a bit to clear it to 0, writing 0 has no effect on bit value). See fields description at the read/write address of the same register.
  fields as VENDOR_INT_EN_CLR_i_0
0x13E VENDOR_INT_STATUS_i_1 ro — Vendor-specific interrupt sources for miscellaneous ULPI alt_int events
  fields as VENDOR_INT_STATUS_i_0
0x13F VENDOR_INT_LATCH_i_1 ro — Vendor-specific interrupt latches for miscellaneous ULPI alt_int events. Cleared upon read, and when low-power mode, serial mode or carkit mode are entered.
  fields as VENDOR_INT_LATCH_i_0
